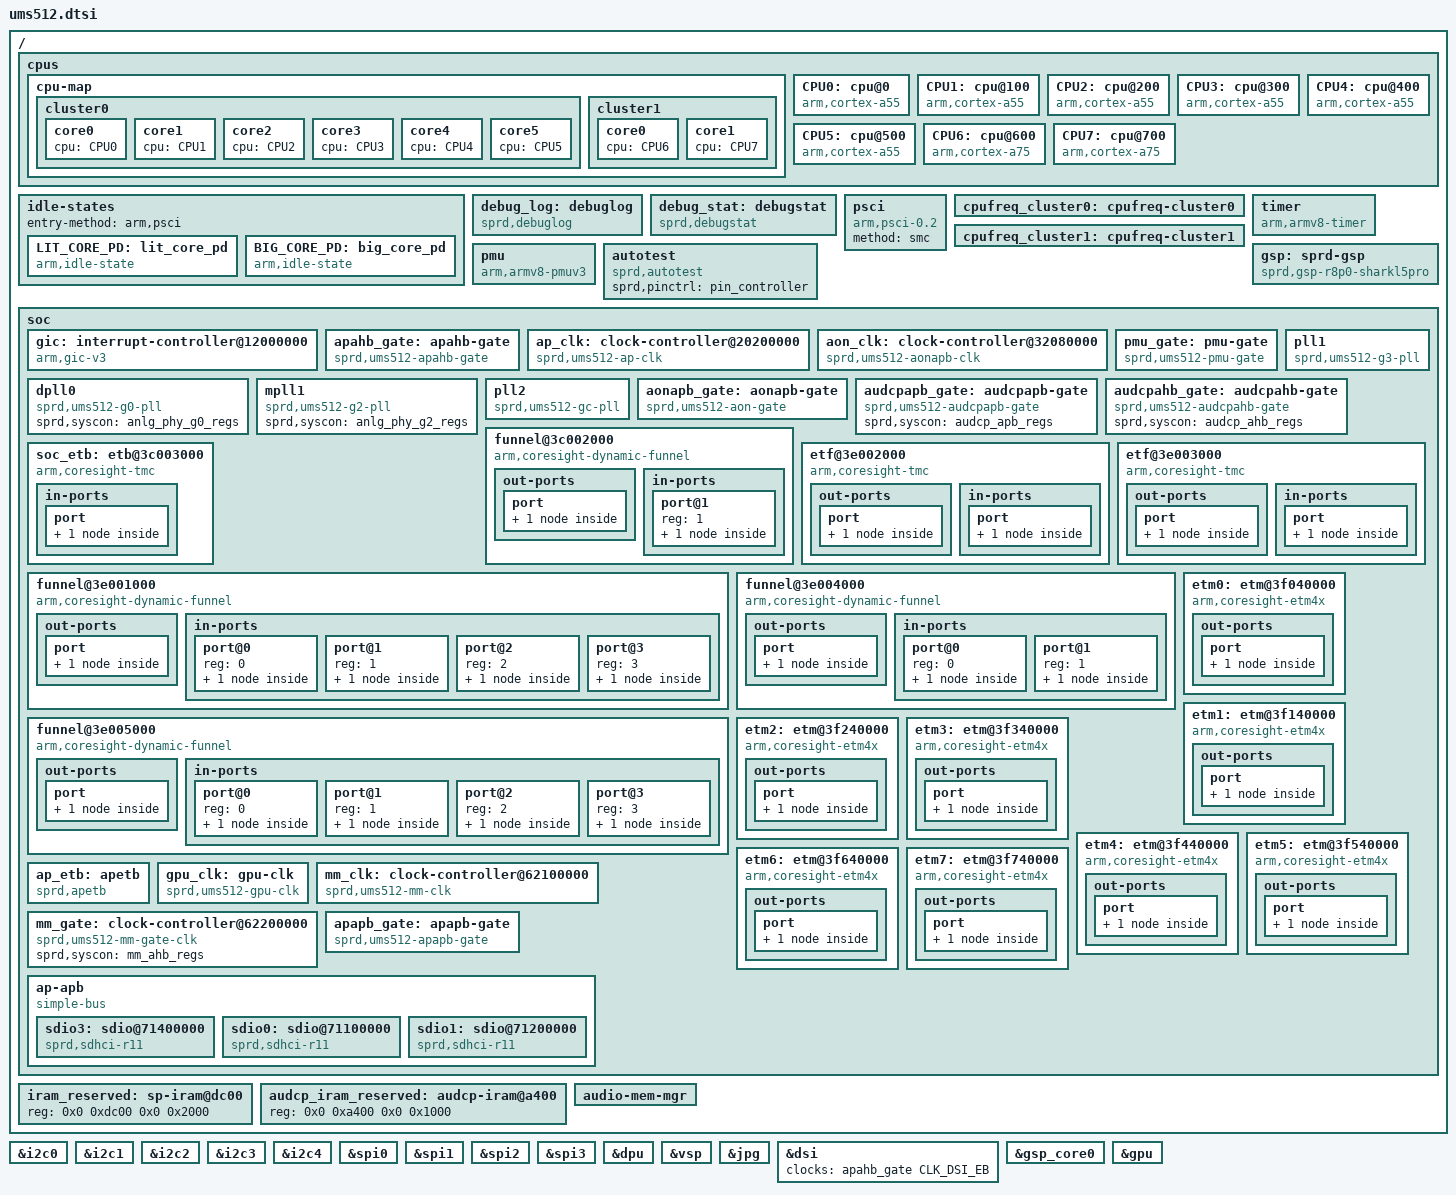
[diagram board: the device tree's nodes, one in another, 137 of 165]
// SPDX-License-Identifier: GPL-2.0-only
/*
 * Unisoc UMS512 SoC DTS file
 *
 * Copyright (C) 2020, Unisoc Inc.
 */

#include <dt-bindings/interrupt-controller/arm-gic.h>
#include <dt-bindings/clock/sprd,ums512-clk.h>
#include "sharkl5Pro.dtsi"
#include "ums512-modem.dtsi"

/ {
	cpuinfo_hardware = "Unisoc ums512";
	soc-module = "UMS512";
	soc-manufacturer = "Spreadtrum";

	cpus {
		#address-cells = <2>;
		#size-cells = <0>;

		cpu-map {
			cluster0 {
				core0 {
					cpu = <&CPU0>;
				};
				core1 {
					cpu = <&CPU1>;
				};
				core2 {
					cpu = <&CPU2>;
				};
				core3 {
					cpu = <&CPU3>;
				};
				core4 {
					cpu = <&CPU4>;
				};
				core5 {
					cpu = <&CPU5>;
				};
			};
			cluster1 {
				core0 {
					cpu = <&CPU6>;
				};
				core1 {
					cpu = <&CPU7>;
				};
			};
		};

		CPU0: cpu@0 {
			device_type = "cpu";
			compatible = "arm,cortex-a55";
			reg = <0x0 0x0>;
			enable-method = "psci";
			cpu-idle-states = <&LIT_CORE_PD>;
			cpufreq-data-v1 = <&cpufreq_cluster0>;
			capacity-dmips-mhz = <544>;
			dynamic-power-coefficient = <102>;
			#cooling-cells = <2>;
			sugov_slack_timer;
		};

		CPU1: cpu@100 {
			device_type = "cpu";
			compatible = "arm,cortex-a55";
			reg = <0x0 0x100>;
			enable-method = "psci";
			cpu-idle-states = <&LIT_CORE_PD>;
			cpufreq-data-v1 = <&cpufreq_cluster0>;
			capacity-dmips-mhz = <544>;
			dynamic-power-coefficient = <102>;
		};

		CPU2: cpu@200 {
			device_type = "cpu";
			compatible = "arm,cortex-a55";
			reg = <0x0 0x200>;
			enable-method = "psci";
			cpu-idle-states = <&LIT_CORE_PD>;
			cpufreq-data-v1 = <&cpufreq_cluster0>;
			capacity-dmips-mhz = <544>;
			dynamic-power-coefficient = <102>;
		};

		CPU3: cpu@300 {
			device_type = "cpu";
			compatible = "arm,cortex-a55";
			reg = <0x0 0x300>;
			enable-method = "psci";
			cpu-idle-states = <&LIT_CORE_PD>;
			cpufreq-data-v1 = <&cpufreq_cluster0>;
			capacity-dmips-mhz = <544>;
			dynamic-power-coefficient = <102>;
		};

		CPU4: cpu@400 {
			device_type = "cpu";
			compatible = "arm,cortex-a55";
			reg = <0x0 0x400>;
			enable-method = "psci";
			cpu-idle-states = <&LIT_CORE_PD>;
			cpufreq-data-v1 = <&cpufreq_cluster0>;
			capacity-dmips-mhz = <544>;
			dynamic-power-coefficient = <102>;
		};

		CPU5: cpu@500 {
			device_type = "cpu";
			compatible = "arm,cortex-a55";
			reg = <0x0 0x500>;
			enable-method = "psci";
			cpu-idle-states = <&LIT_CORE_PD>;
			cpufreq-data-v1 = <&cpufreq_cluster0>;
			capacity-dmips-mhz = <544>;
			dynamic-power-coefficient = <102>;
		};

		CPU6: cpu@600 {
			device_type = "cpu";
			compatible = "arm,cortex-a75";
			reg = <0x0 0x600>;
			enable-method = "psci";
			cpu-idle-states = <&BIG_CORE_PD>;
			cpufreq-data-v1 = <&cpufreq_cluster1>;
			capacity-dmips-mhz = <1024>;
			dynamic-power-coefficient = <501>;
			#cooling-cells = <2>;
		};

		CPU7: cpu@700 {
			device_type = "cpu";
			compatible = "arm,cortex-a75";
			reg = <0x0 0x700>;
			enable-method = "psci";
			cpu-idle-states = <&BIG_CORE_PD>;
			cpufreq-data-v1 = <&cpufreq_cluster1>;
			capacity-dmips-mhz = <1024>;
			dynamic-power-coefficient = <501>;
		};
	};

	idle-states {
		entry-method = "arm,psci";
		LIT_CORE_PD: lit_core_pd {
			compatible = "arm,idle-state";
			entry-latency-us = <1000>;
			exit-latency-us = <500>;
			min-residency-us = <2500>;
			local-timer-stop;
			arm,psci-suspend-param = <0x00010000>;
		};

		BIG_CORE_PD: big_core_pd {
			compatible = "arm,idle-state";
			entry-latency-us = <4000>;
			exit-latency-us = <4000>;
			min-residency-us = <10000>;
			local-timer-stop;
			arm,psci-suspend-param = <0x00010000>;
		};
	};

	debug_log: debuglog {
		compatible                        = "sprd,debuglog";
		sprd,pdbg-irq-domain-gic          = "GICv3";
		sprd,pdbg-irq-domain-gpio         = "sprd-gpio";
		sprd,pdbg-irq-domain-ana          = "spi4.0";
		sprd,pdbg-irq-domain-ana-eic      = "32100000.spi:pmic@0:gpio@280";
		sprd,pdbg-irq-domain-ap-eic-sync  = "320200c0.gpio";
	};

	debug_stat: debugstat {
		compatible = "sprd,debugstat";
		soc_slp_cnt_reg = <&pmu_apb_regs REG_PMU_APB_RF_PUB_SYS_DEEP_SLEEP_CNT 0xff>;
	};

	psci {
		compatible = "arm,psci-0.2";
		method = "smc";
	};

	cpufreq_cluster0: cpufreq-cluster0 {
		sprd,temp-threshold = <65>;
		nvmem-cell-names = "dvfs_bin";
		nvmem-cells = <&dvfs_bin_cpu0>;
		sprd,multi-version;
		sprd,cpufreq-boost;
		sprd,pmic-type = <0>;
		sprd,cluster-cpumask = <0x3f>;
		sprd,transition-delay = <500>;
	};

	cpufreq_cluster1: cpufreq-cluster1 {
		sprd,temp-threshold = <65>;
		nvmem-cell-names = "dvfs_bin";
		nvmem-cells = <&dvfs_bin_cpu1>;
		sprd,multi-version;
		sprd,multi-supply;
		sprd,cpufreq-boost;
		sprd,pmic-type = <1>;
		sprd,pmic-type-v2 = <0>;
		sprd,cluster-cpumask = <0xc0>;
		sprd,transition-delay = <500>;
	};

	timer {
		compatible = "arm,armv8-timer";
		interrupts = <GIC_PPI 13 IRQ_TYPE_LEVEL_HIGH>, /* Physical Secure PPI */
			<GIC_PPI 14 IRQ_TYPE_LEVEL_HIGH>, /* Physical Non-Secure PPI */
			<GIC_PPI 11 IRQ_TYPE_LEVEL_HIGH>, /* Virtual PPI */
			<GIC_PPI 10 IRQ_TYPE_LEVEL_HIGH>; /* Hipervisor PPI */
		arm,no-tick-in-suspend;
	};

	pmu {
		compatible = "arm,armv8-pmuv3";
		interrupts = <GIC_SPI 112 IRQ_TYPE_LEVEL_HIGH>,
			<GIC_SPI 113 IRQ_TYPE_LEVEL_HIGH>,
			<GIC_SPI 114 IRQ_TYPE_LEVEL_HIGH>,
			<GIC_SPI 115 IRQ_TYPE_LEVEL_HIGH>,
			<GIC_SPI 116 IRQ_TYPE_LEVEL_HIGH>,
			<GIC_SPI 117 IRQ_TYPE_LEVEL_HIGH>,
			<GIC_SPI 118 IRQ_TYPE_LEVEL_HIGH>,
			<GIC_SPI 119 IRQ_TYPE_LEVEL_HIGH>;
	};

	autotest: autotest {
		compatible = "sprd,autotest";
		sprd,pinctrl = <&pin_controller>;
	};

	gsp: sprd-gsp {
		compatible = "sprd,gsp-r8p0-sharkl5pro";
		name = "sprd-gsp";
		core-cnt = <1>;
		io-cnt = <7>;
		cores = <&gsp_core0>;
	};

	soc {
		gic: interrupt-controller@12000000 {
			compatible = "arm,gic-v3";
			#interrupt-cells = <3>;
			#address-cells = <2>;
			#size-cells = <2>;
			ranges;
			redistributor-stride = <0x0 0x20000>;	/* 128KB stride */
			#redistributor-regions = <1>;
			interrupt-controller;
			reg = <0x0 0x12000000 0 0x20000>,	/* GICD */
			      <0x0 0x12040000 0 0x100000>;	/* GICR */
			interrupts = <GIC_PPI 9 IRQ_TYPE_LEVEL_HIGH>;
		};

		apahb_gate: apahb-gate {
			compatible = "sprd,ums512-apahb-gate";
			sprd,syscon = <&ap_ahb_regs>; /* 0x20100000 */
			clocks = <&ext_26m>;
			clock-names = "ext-26m";
			#clock-cells = <1>;
			#reset-cells = <1>;
		};

		ap_clk: clock-controller@20200000 {
			compatible = "sprd,ums512-ap-clk";
			reg = <0 0x20200000 0 0x1000>;
			clocks = <&ext_26m>;
			clock-names = "ext-26m";
			#clock-cells = <1>;
		};

		aon_clk: clock-controller@32080000 {
			compatible = "sprd,ums512-aonapb-clk";
			reg = <0 0x32080000 0 0x1000>;
			clocks = <&ext_26m>, <&rco_100m>, <&ext_32k>,
				 <&ext_4m>;
			clock-names = "ext-26m", "rco-100m", "ext-32k",
				      "ext-4m";
			#clock-cells = <1>;
		};

		pmu_gate: pmu-gate {
			compatible = "sprd,ums512-pmu-gate";
			sprd,syscon = <&pmu_apb_regs>; /* 0x327e0000 */
			clocks = <&ext_26m>;
			clock-names = "ext-26m";
			#clock-cells = <1>;
			#reset-cells = <1>;
		};

		dpll0: dpll0 {
			compatible = "sprd,ums512-g0-pll";
			sprd,syscon = <&anlg_phy_g0_regs>; /* 0x32390000 */
			#clock-cells = <1>;
		};

		mpll1: mpll1 {
			compatible = "sprd,ums512-g2-pll";
			sprd,syscon = <&anlg_phy_g2_regs>; /* 0x323b0000 */
			#clock-cells = <1>;
		};

		pll1: pll1 {
			compatible = "sprd,ums512-g3-pll";
			sprd,syscon = <&anlg_phy_g3_regs>; /* 0x323c0000 */
			clocks = <&ext_26m>;
			clock-names = "ext-26m";
			#clock-cells = <1>;
		};

		pll2: pll2 {
			compatible = "sprd,ums512-gc-pll";
			sprd,syscon = <&anlg_phy_gc_regs>; /* 0x323e0000 */
			clocks = <&ext_26m>;
			clock-names = "ext-26m";
			#clock-cells = <1>;
		};

		aonapb_gate: aonapb-gate {
			compatible = "sprd,ums512-aon-gate";
			sprd,syscon = <&aon_apb_regs>; /* 0x327d0000 */
			clocks = <&ext_26m>;
			clock-names = "ext-26m";
			#clock-cells = <1>;
			#reset-cells = <1>;
		};

		audcpapb_gate: audcpapb-gate {
			compatible = "sprd,ums512-audcpapb-gate";
			sprd,syscon = <&audcp_apb_regs>; /* 0x3350d000 */
			#clock-cells = <1>;
			#reset-cells = <1>;
		};

		audcpahb_gate: audcpahb-gate {
			compatible = "sprd,ums512-audcpahb-gate";
			sprd,syscon = <&audcp_ahb_regs>; /* 0x335e0000 */
			#clock-cells = <1>;
			#reset-cells = <1>;
		};

		/* soc_funnel */
		funnel@3c002000 {
			compatible = "arm,coresight-dynamic-funnel", "arm,primecell";
			reg = <0 0x3c002000 0 0x1000>;
			clocks = <&ext_26m>;
			clock-names = "apb_pclk";

			out-ports {
				port {
					funnel_soc_out_port: endpoint {
						remote-endpoint = <&etb_in>;
					};
				};
			};

			in-ports {
				#address-cells = <1>;
				#size-cells = <0>;

				port@1 {
					reg = <1>;
					funnel_soc_in_port: endpoint {
						remote-endpoint =
						<&funnel_corinth_out_port>;
					};
				};
			};
		};

		/* soc_etf */
		soc_etb: etb@3c003000 {
			compatible = "arm,coresight-tmc", "arm,primecell";
			reg = <0 0x3c003000 0 0x1000>;
			clocks = <&ext_26m>;
			clock-names = "apb_pclk";

			in-ports {
				port {
					etb_in: endpoint {
						remote-endpoint =
						<&funnel_soc_out_port>;
					};
				};
			};
		};

		/* apcpu funnel lit core3/4/5/7*/
		funnel@3e001000 {
			compatible = "arm,coresight-dynamic-funnel", "arm,primecell";
			reg = <0 0x3e001000 0 0x1000>;
			clocks = <&ext_26m>;
			clock-names = "apb_pclk";

			out-ports {
				port {
					funnel_corinth_lit_out_port: endpoint {
						remote-endpoint =
						<&corinth_etf_lit_in>;
					};
				};
			};

			in-ports {
				#address-cells = <1>;
				#size-cells = <0>;

				port@0 {
					reg = <0>;
					funnel_core_in_port3: endpoint {
						remote-endpoint = <&etm3_out>;
					};
				};

				port@1 {
					reg = <1>;
					funnel_core_in_port4: endpoint {
						remote-endpoint = <&etm4_out>;
					};
				};

				port@2 {
					reg = <2>;
					funnel_core_in_port5: endpoint {
						remote-endpoint = <&etm5_out>;
					};
				};

				port@3 {
					reg = <3>;
					funnel_core_in_port7: endpoint {
						remote-endpoint = <&etm7_out>;
					};
				};
			};
		};

		/* apcpu lit etf */
		etf@3e002000 {
			compatible = "arm,coresight-tmc", "arm,primecell";
			reg = <0 0x3e002000 0 0x1000>;
			clocks = <&ext_26m>;
			clock-names = "apb_pclk";

			out-ports {
				port {
					corinth_etf_lit_out: endpoint {
						remote-endpoint =
						<&funnel_corinth_from_lit_in_port>;
					};
				};
			};

			in-ports {
				port {
					corinth_etf_lit_in: endpoint {
						remote-endpoint =
						<&funnel_corinth_lit_out_port>;
					};
				};
			};
		};

		/* apcpu big etf */
		etf@3e003000 {
			compatible = "arm,coresight-tmc", "arm,primecell";
			reg = <0 0x3e003000 0 0x1000>;
			clocks = <&ext_26m>;
			clock-names = "apb_pclk";

			out-ports {
				port {
					corinth_etf_big_out: endpoint {
						remote-endpoint =
						<&funnel_corinth_from_big_in_port>;
					};
				};
			};

			in-ports {
				port {
					corinth_etf_big_in: endpoint {
						remote-endpoint =
						<&funnel_corinth_big_out_port>;
					};
				};
			};
		};

		/* funnel to Soc */
		funnel@3e004000 {
			compatible = "arm,coresight-dynamic-funnel", "arm,primecell";
			reg = <0 0x3e004000 0 0x1000>;
			clocks = <&ext_26m>;
			clock-names = "apb_pclk";

			out-ports {
				port {
					funnel_corinth_out_port: endpoint {
						remote-endpoint =
						<&funnel_soc_in_port>;
					};
				};
			};

			in-ports {
				#address-cells = <1>;
				#size-cells = <0>;

				port@0 {
					reg = <0>;
					funnel_corinth_from_lit_in_port: endpoint {
						remote-endpoint = <&corinth_etf_lit_out>;
					};
				};

				port@1 {
					reg = <1>;
					funnel_corinth_from_big_in_port: endpoint {
						remote-endpoint = <&corinth_etf_big_out>;
					};
				};
			};
		};

		/* apcpu funnel big core0/1/2/6*/
		funnel@3e005000 {
			compatible = "arm,coresight-dynamic-funnel", "arm,primecell";
			reg = <0 0x3e005000 0 0x1000>;
			clocks = <&ext_26m>;
			clock-names = "apb_pclk";

			out-ports {
				port {
					funnel_corinth_big_out_port: endpoint {
						remote-endpoint = <&corinth_etf_big_in>;
					};
				};
			};

			in-ports {
				#address-cells = <1>;
				#size-cells = <0>;

				port@0 {
					reg = <0>;
					funnel_core_in_port0: endpoint {
						remote-endpoint = <&etm0_out>;
					};
				};

				port@1 {
					reg = <1>;
					funnel_core_in_port1: endpoint {
						remote-endpoint = <&etm1_out>;
					};
				};

				port@2 {
					reg = <2>;
					funnel_core_in_port2: endpoint {
						remote-endpoint = <&etm2_out>;
					};
				};

				port@3 {
					reg = <3>;
					funnel_core_in_port6: endpoint {
						remote-endpoint = <&etm6_out>;
					};
				};
			};
		};

		etm0: etm@3f040000 {
			compatible = "arm,coresight-etm4x", "arm,primecell";
			reg = <0 0x3f040000 0 0x1000>;
			cpu = <&CPU0>;
			clocks = <&ext_26m>, <&aon_clk CLK_CSSYS>, <&pll2 CLK_TWPLL_512M>;
			clock-names = "apb_pclk", "clk_cs", "cs_src";

			out-ports {
				port {
					etm0_out: endpoint {
						remote-endpoint =
						<&funnel_core_in_port0>;
					};
				};
			};
		};

		etm1: etm@3f140000 {
			compatible = "arm,coresight-etm4x", "arm,primecell";
			reg = <0 0x3f140000 0 0x1000>;
			cpu = <&CPU1>;
			clocks = <&ext_26m>, <&aon_clk CLK_CSSYS>, <&pll2 CLK_TWPLL_512M>;
			clock-names = "apb_pclk", "clk_cs", "cs_src";

			out-ports {
				port {
					etm1_out: endpoint {
						remote-endpoint =
						<&funnel_core_in_port1>;
					};
				};
			};
		};

		etm2: etm@3f240000 {
			compatible = "arm,coresight-etm4x", "arm,primecell";
			reg = <0 0x3f240000 0 0x1000>;
			cpu = <&CPU2>;
			clocks = <&ext_26m>, <&aon_clk CLK_CSSYS>, <&pll2 CLK_TWPLL_512M>;
			clock-names = "apb_pclk", "clk_cs", "cs_src";

			out-ports {
				port {
					etm2_out: endpoint {
						remote-endpoint =
						<&funnel_core_in_port2>;
					};
				};
			};
		};

		etm3: etm@3f340000 {
			compatible = "arm,coresight-etm4x", "arm,primecell";
			reg = <0 0x3f340000 0 0x1000>;
			cpu = <&CPU3>;
			clocks = <&ext_26m>, <&aon_clk CLK_CSSYS>, <&pll2 CLK_TWPLL_512M>;
			clock-names = "apb_pclk", "clk_cs", "cs_src";

			out-ports {
				port {
					etm3_out: endpoint {
						remote-endpoint =
						<&funnel_core_in_port3>;
					};
				};
			};
		};

		etm4: etm@3f440000 {
			compatible = "arm,coresight-etm4x", "arm,primecell";
			reg = <0 0x3f440000 0 0x1000>;
			cpu = <&CPU4>;
			clocks = <&ext_26m>, <&aon_clk CLK_CSSYS>, <&pll2 CLK_TWPLL_512M>;
			clock-names = "apb_pclk", "clk_cs", "cs_src";

			out-ports {
				port {
					etm4_out: endpoint {
						remote-endpoint =
						<&funnel_core_in_port4>;
					};
				};
			};
		};

		etm5: etm@3f540000 {
			compatible = "arm,coresight-etm4x", "arm,primecell";
			reg = <0 0x3f540000 0 0x1000>;
			cpu = <&CPU5>;
			clocks = <&ext_26m>, <&aon_clk CLK_CSSYS>, <&pll2 CLK_TWPLL_512M>;
			clock-names = "apb_pclk", "clk_cs", "cs_src";

			out-ports {
				port {
					etm5_out: endpoint {
						remote-endpoint =
						<&funnel_core_in_port5>;
					};
				};
			};
		};

		etm6: etm@3f640000 {
			compatible = "arm,coresight-etm4x", "arm,primecell";
			reg = <0 0x3f640000 0 0x1000>;
			cpu = <&CPU6>;
			clocks = <&ext_26m>, <&aon_clk CLK_CSSYS>, <&pll2 CLK_TWPLL_512M>;
			clock-names = "apb_pclk", "clk_cs", "cs_src";

			out-ports {
				port {
					etm6_out: endpoint {
						remote-endpoint =
						<&funnel_core_in_port6>;
					};
				};
			};
		};

		etm7: etm@3f740000 {
			compatible = "arm,coresight-etm4x", "arm,primecell";
			reg = <0 0x3f740000 0 0x1000>;
			cpu = <&CPU7>;
			clocks = <&ext_26m>, <&aon_clk CLK_CSSYS>, <&pll2 CLK_TWPLL_512M>;
			clock-names = "apb_pclk", "clk_cs", "cs_src";

			out-ports {
				port {
					etm7_out: endpoint {
						remote-endpoint =
						<&funnel_core_in_port7>;
					};
				};
			};
		};

		ap_etb: apetb {
			compatible = "sprd,apetb";
			apetb-source = <&etm0 &etm1	&etm2 &etm3 &etm4 &etm5	&etm6 &etm7>;
			apetb-sink = <&soc_etb>;
		};

		gpu_clk: gpu-clk {
			compatible = "sprd,ums512-gpu-clk";
			sprd,syscon = <&gpu_apb_regs>; /* 0x60100000 */
			clocks = <&ext_26m>;
			clock-names = "ext-26m";
			#clock-cells = <1>;
			#reset-cells = <1>;
		};

		mm_clk: clock-controller@62100000 {
			compatible = "sprd,ums512-mm-clk";
			reg = <0 0x62100000 0 0x1000>;
			clocks = <&ext_26m>;
			clock-names = "ext-26m";
			#clock-cells = <1>;
		};

		mm_gate: clock-controller@62200000 {
			compatible = "sprd,ums512-mm-gate-clk";
			sprd,syscon = <&mm_ahb_regs>;
			#clock-cells = <1>;
			#reset-cells = <1>;
		};

		apapb_gate: apapb-gate {
			compatible = "sprd,ums512-apapb-gate";
			sprd,syscon = <&ap_apb_regs>; /* 0x71000000 */
			clocks = <&ext_26m>;
			clock-names = "ext-26m";
			#clock-cells = <1>;
			#reset-cells = <1>;
		};

		ap-apb {
			compatible = "simple-bus";
			#address-cells = <2>;
			#size-cells = <2>;
			ranges;

			sdio3: sdio@71400000 {
				compatible = "sprd,sdhci-r11";
				reg = <0 0x71400000 0 0x1000>;
				interrupts = <GIC_SPI 10 IRQ_TYPE_LEVEL_HIGH>;
				clock-names = "sdio", "enable";
				clocks = <&ap_clk CLK_EMMC_2X>,
					 <&apapb_gate CLK_EMMC_EB>;
				assigned-clocks = <&ap_clk CLK_EMMC_2X>;
				assigned-clock-parents = <&pll1 CLK_RPLL>;
			};

			sdio0: sdio@71100000 {
				compatible = "sprd,sdhci-r11";
				reg = <0 0x71100000 0 0x1000>;
				interrupts = <GIC_SPI 19 IRQ_TYPE_LEVEL_HIGH>;
				clock-names = "sdio", "enable";
				clocks = <&ap_clk CLK_SDIO0_2X>,
					 <&apapb_gate CLK_SDIO0_EB>;
				assigned-clocks = <&ap_clk CLK_SDIO0_2X>;
				assigned-clock-parents = <&pll1 CLK_RPLL>;
				sd-detect-pol-syscon = <&aon_apb_regs
					REG_AON_APB_RF_AP_SDIO0_PHY_CTRL
					MASK_AON_APB_RF_AP_SDIO0_CARD_PRESENT_32K>;
				sd-hotplug-protect-en-syscon = <&aon_apb_regs
					REG_AON_APB_RF_AP_SDIO0_PHY_CTRL
					MASK_AON_APB_RF_AP_SDIO0_CARD_PROTECT_32K>;
				sd-hotplug-debounce-en-syscon = <&aon_apb_regs
					REG_AON_APB_RF_AP_SDIO0_PHY_CTRL
					MASK_AON_APB_RF_AP_SDIO0_CARDDET_DBNC_EN_32K>;
				sd-hotplug-debounce-cn-syscon = <&aon_apb_regs
					REG_AON_APB_RF_AP_SDIO0_PHY_CTRL
					MASK_AON_APB_RF_AP_SDIO0_CARDDET_DBNC_THD_32K>;
			};

			sdio1: sdio@71200000 {
				compatible = "sprd,sdhci-r11";
				reg = <0 0x71200000 0 0x1000>;
				interrupts = <GIC_SPI 20 IRQ_TYPE_LEVEL_HIGH>;
				clock-names = "sdio", "enable";
				clocks = <&ap_clk CLK_SDIO1_2X>,
					 <&apapb_gate CLK_SDIO1_EB>;
				assigned-clocks = <&ap_clk CLK_SDIO1_2X>;
				assigned-clock-parents = <&pll2 CLK_LPLL_409M6>;
			};
		};
	};

	iram_reserved: sp-iram@dc00 {
		reg = <0x0 0xdc00 0x0 0x2000>;
	};

	audcp_iram_reserved: audcp-iram@a400 {
		reg = <0x0 0xa400 0x0 0x1000>;
	};

	audio-mem-mgr {
		memory-region = <&audio_reserved &audiodsp_reserved>;
	};
};

&i2c0 {
	clock-names ="enable", "i2c", "source";
	clocks = <&apapb_gate CLK_I2C0_EB>,
		 <&ap_clk CLK_AP_I2C0>, <&ext_26m>;
};

&i2c1 {
	clock-names ="enable", "i2c", "source";
	clocks = <&apapb_gate CLK_I2C1_EB>,
		 <&ap_clk CLK_AP_I2C1>, <&ext_26m>;
};

&i2c2 {
	clock-names ="enable", "i2c", "source";
	clocks = <&apapb_gate CLK_I2C2_EB>,
		 <&ap_clk CLK_AP_I2C2>, <&ext_26m>;
};

&i2c3 {
	clock-names ="enable", "i2c", "source";
	clocks = <&apapb_gate CLK_I2C3_EB>,
		 <&ap_clk CLK_AP_I2C3>, <&ext_26m>;
};

&i2c4 {
	clock-names ="enable", "i2c", "source";
	clocks = <&apapb_gate CLK_I2C4_EB>,
		 <&ap_clk CLK_AP_I2C4>, <&ext_26m>;
};

&spi0 {
	clock-names = "enable", "spi", "source";
	clocks = <&apapb_gate CLK_SPI0_EB>,
		 <&ap_clk CLK_AP_SPI0>, <&pll2 CLK_TWPLL_192M>;
};

&spi1 {
	clock-names = "enable", "spi", "source";
	clocks = <&apapb_gate CLK_SPI1_EB>,
		 <&ap_clk CLK_AP_SPI1>, <&pll2 CLK_TWPLL_192M>;
};

&spi2 {
	clock-names = "enable", "spi", "source";
	clocks = <&apapb_gate CLK_SPI2_EB>,
		 <&ap_clk CLK_AP_SPI2>, <&pll2 CLK_TWPLL_192M>;
};

&spi3 {
	clock-names = "enable", "spi", "source";
	clocks = <&apapb_gate CLK_SPI3_EB>,
		 <&ap_clk CLK_AP_SPI3>, <&pll2 CLK_TWPLL_192M>;
};

&dpu {
	clock-names = "clk_src_96m",
			"clk_src_128m",
			"clk_src_153m6",
			"clk_src_192m",
			"clk_src_256m",
			"clk_src_307m2",
			"clk_src_384m",
			"clk_dpu_core",
			"clk_dpu_dpi",
			"clk_ap_ahb_disp_eb";

	clocks = <&pll2 CLK_TWPLL_96M>,
		<&pll2 CLK_TWPLL_128M>,
		<&pll2 CLK_TWPLL_153M6>,
		<&pll2 CLK_TWPLL_192M>,
		<&pll2 CLK_TWPLL_256M>,
		<&pll2 CLK_TWPLL_307M2>,
		<&pll2 CLK_TWPLL_384M>,
		<&ap_clk CLK_DISPC0>,
		<&ap_clk CLK_DISPC0_DPI>,
		<&apahb_gate CLK_DISPC_EB>;
};

&vsp {
	clock-names = "clk_ahb_gate_vsp_eb",
			"clk_src_256m",
			"clk_src_307m2",
			"clk_src_384m",
			"clk_vsp";
	clocks = <&apahb_gate CLK_VSP_EB>,
			<&pll2 CLK_TWPLL_256M>,
			<&pll2 CLK_TWPLL_307M2>,
			<&pll2 CLK_TWPLL_384M>,
			<&ap_clk CLK_VSP>;
};

&jpg {
	clock-names = "jpg_domain_eb",
			"jpg_dev_eb",
			"jpg_ckg_eb",
			"jpg_clk",
			"clk_src_76m8",
			"clk_src_128m",
			"clk_src_256m",
			"clk_src_384m";

	clocks = <&aonapb_gate CLK_MM_EB>,
		<&mm_gate CLK_MM_JPG_EB>,
		<&mm_gate CLK_MM_CKG_EB>,
		<&mm_clk CLK_JPG>,
		<&pll2 CLK_TWPLL_76M8>,
		<&pll2 CLK_TWPLL_128M>,
		<&pll2 CLK_TWPLL_256M>,
		<&pll2 CLK_TWPLL_384M>;
};

&dsi {
	clock-names = "clk_ap_ahb_dsi_eb";
	clocks = <&apahb_gate CLK_DSI_EB>;
};

&gsp_core0 {
	clock-names =   "clk_dpu_core_src",
			"clk_dpu_core",
			"clk_ap_ahb_disp_eb";

	clocks =        <&pll2 CLK_TWPLL_384M>,
			<&ap_clk CLK_DISPC0>,
			<&apahb_gate CLK_DISPC_EB>;
};
&gpu {
	clocks = <&aonapb_gate CLK_GPU_EB>,
		<&gpu_clk CLK_GPU_CORE_EB>,
		<&gpu_clk CLK_GPU_MEM_EB>,
		<&gpu_clk CLK_GPU_SYS_EB>,
		<&pll2 CLK_TWPLL_384M>,
		<&pll2 CLK_TWPLL_512M>,
		<&pll2 CLK_LPLL_614M4>,
		<&pll2 CLK_TWPLL_768M>,
		<&pll2 CLK_GPLL>;
};
